# PY32L0xx_DFP register map
Vendor: Puya; Series: PY32L0; File version: 1.0.0
CPU: CM0+ r0p1, little endian, no MPU, no FPU, 4 interrupt priority bits
Registers are 32-bit, read-write, reset 0x0 unless marked. A register's access mark holds for its fields unless they carry their own. Offsets are from the block's base; [hi:lo] are bit positions; {n}, {i} and the like mark numbered series.

## IWDG — Independent watchdog
Base 0x40003000
0x00 KR wo — Key register (IWDG_KR)
  [15:0] KEY — Key value
0x04 PR — Prescaler register (IWDG_PR)
  [2:0] PR — Prescaler divider
0x08 RLR reset 0xFFF — Reload register (IWDG_RLR)
  [11:0] RL — Watchdog counter reload value
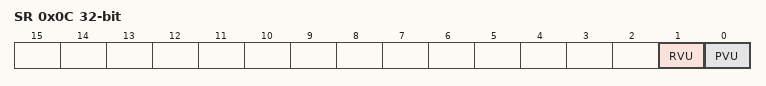
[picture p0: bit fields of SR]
0x0C SR ro — Status register (IWDG_SR)
  [1] RVU — Watchdog counter reload value update
  [0] PVU — Watchdog prescaler value update

## TIM1 — Advanced timer
Base 0x40012C00
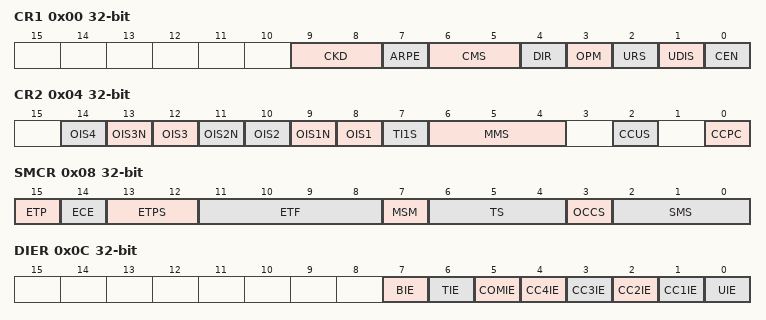
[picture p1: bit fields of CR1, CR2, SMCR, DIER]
0x00 CR1
  [9:8] CKD, [7] ARPE, [6:5] CMS, [4] DIR, [3] OPM, [2] URS, [1] UDIS, [0] CEN
0x04 CR2 (reset mask 0xF8)
  [2n+6] OIS{n} (n=1..4), [13] OIS3N, [11] OIS2N, [9] OIS1N, [7] TI1S, [6:4] MMS, [2] CCUS, [0] CCPC
0x08 SMCR (reset mask 0xFFF7)
  [15] ETP, [14] ECE, [13:12] ETPS, [11:8] ETF, [7] MSM, [6:4] TS, [3] OCCS, [2:0] SMS
0x0C DIER (reset mask 0x5F5F)
  [7] BIE, [6] TIE, [5] COMIE, [n] CC{n}IE (n=1..4), [0] UIE
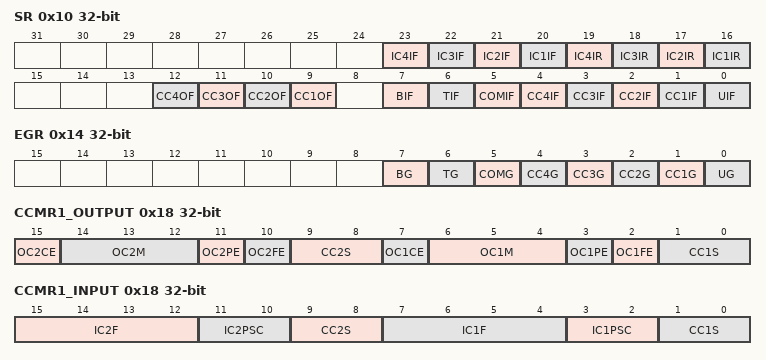
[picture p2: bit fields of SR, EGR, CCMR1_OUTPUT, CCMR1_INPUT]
0x10 SR (reset mask 0x1E5F)
  [23] IC4IF — desc IC3IF
  [22] IC3IF
  [21] IC2IF
  [20] IC1IF
  [19] IC4IR — desc IC3IR
  [18] IC3IR
  [17] IC2IR
  [16] IC1IR
  [n+8] CC{n}OF (n=1..4)
  [7] BIF
  [6] TIF
  [5] COMIF
  [n] CC{n}IF (n=1..4)
  [0] UIF
0x14 EGR wo (reset mask 0x5F)
  [7] BG
  [6] TG
  [5] COMG
  [4] CC4G
  [3] CC3G
  [2] CC2G
  [1] CC1G — Capture/Compare 1 Generation
  [0] UG
0x18 CCMR1_OUTPUT
  [15] OC2CE, [14:12] OC2M, [11] OC2PE, [10] OC2FE, [9:8] CC2S, [7] OC1CE, [6:4] OC1M, [3] OC1PE, [2] OC1FE, [1:0] CC1S
0x18 CCMR1_INPUT (alternate view of CCMR1_OUTPUT)
  [15:12] IC2F, [11:10] IC2PSC, [9:8] CC2S, [7:4] IC1F, [3:2] IC1PSC, [1:0] CC1S
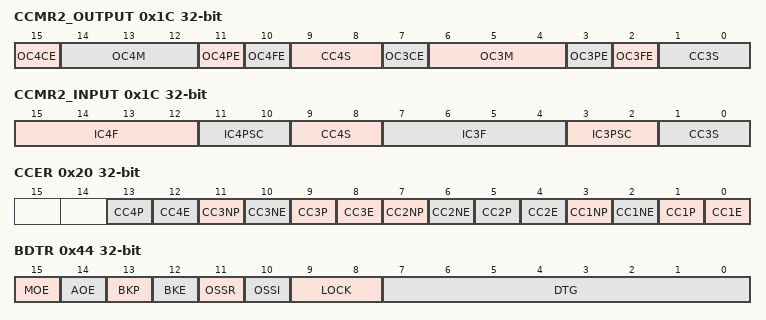
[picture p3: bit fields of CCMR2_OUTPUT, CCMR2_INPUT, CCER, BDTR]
0x1C CCMR2_OUTPUT
  [15] OC4CE, [14:12] OC4M, [11] OC4PE, [10] OC4FE, [9:8] CC4S, [7] OC3CE, [6:4] OC3M, [3] OC3PE, [2] OC3FE, [1:0] CC3S
0x1C CCMR2_INPUT (alternate view of CCMR2_OUTPUT)
  [15:12] IC4F, [11:10] IC4PSC, [9:8] CC4S, [7:4] IC3F, [3:2] IC3PSC, [1:0] CC3S
0x20 CCER (reset mask 0x3333)
  [4n-3] CC{n}P (n=1..4), [4n-4] CC{n}E (n=1..4), [11] CC3NP, [10] CC3NE, [7] CC2NP, [6] CC2NE, [3] CC1NP, [2] CC1NE
0x24 CNT
  [15:0] CNT
0x28 PSC
  [15:0] PSC
0x2C ARR reset 0xFFFF
  [15:0] ARR
0x30 RCR reset 0xFFFF
  [7:0] REP
{0x30+4i} CCR{i} (i=1..4)
  [15:0] CCR{i}
0x44 BDTR
  [15] MOE, [14] AOE, [13] BKP, [12] BKE, [11] OSSR, [10] OSSI, [9:8] LOCK, [7:0] DTG

## TIM14 — General purpose timer
Base 0x40002000
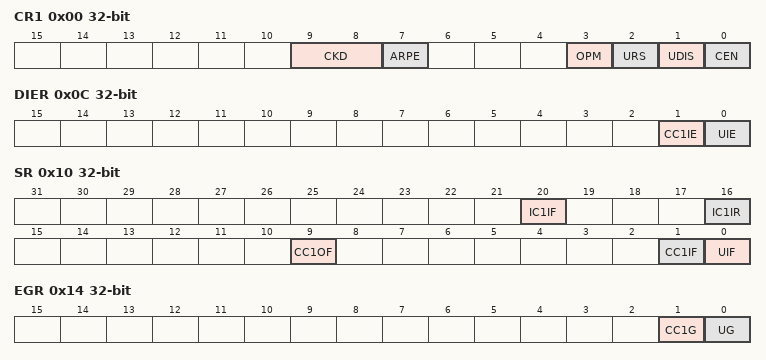
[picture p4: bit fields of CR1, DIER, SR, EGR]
0x00 CR1
  [9:8] CKD, [7] ARPE, [3] OPM, [2] URS, [1] UDIS, [0] CEN
0x0C DIER
  [1] CC1IE, [0] UIE
0x10 SR (reset mask 0x1E5F)
  [20] IC1IF, [16] IC1IR, [9] CC1OF, [1] CC1IF, [0] UIF
0x14 EGR wo
  [1] CC1G — Capture/Compare 1 Generation
  [0] UG
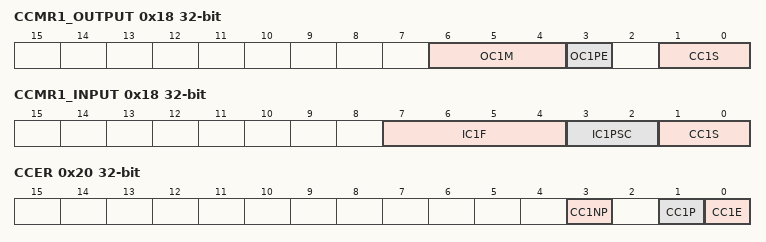
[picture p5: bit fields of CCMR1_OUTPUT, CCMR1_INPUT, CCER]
0x18 CCMR1_OUTPUT
  [6:4] OC1M, [3] OC1PE, [1:0] CC1S
0x18 CCMR1_INPUT (alternate view of CCMR1_OUTPUT)
  [7:4] IC1F, [3:2] IC1PSC, [1:0] CC1S
0x20 CCER (reset mask 0x3333)
  [3] CC1NP, [1] CC1P, [0] CC1E
0x24 CNT
  [15:0] CNT
0x28 PSC
  [15:0] PSC
0x2C ARR reset 0xFFFF
  [15:0] ARR
0x34 CCR1
  [15:0] CCR1
0x50 OR
  [1:0] TI1_RMP

## SYSCFG — System configuration controller
Base 0x40010000
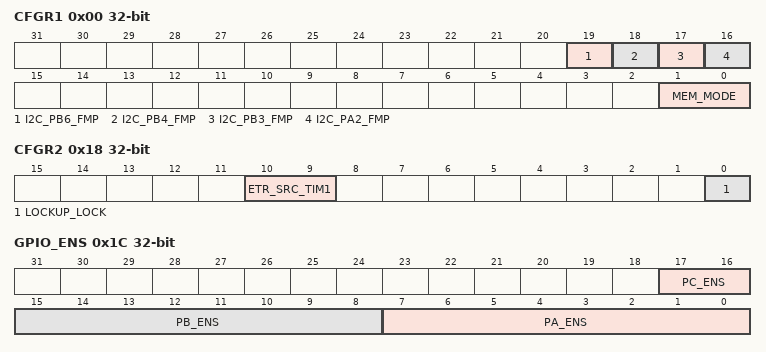
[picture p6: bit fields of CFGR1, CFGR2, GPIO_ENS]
0x00 CFGR1 — SYSCFG configuration register 1
  [19] I2C_PB6_FMP
  [18] I2C_PB4_FMP
  [17] I2C_PB3_FMP
  [16] I2C_PA2_FMP
  [1:0] MEM_MODE — Memory mapping selection bits
0x18 CFGR2 — SYSCFG configuration register 2
  [10:9] ETR_SRC_TIM1 — TIM1 ETR source selection
  [0] LOCKUP_LOCK — Cortex-M0+ LOCKUP bit enable bit
0x1C GPIO_ENS
  [17:16] PC_ENS, [15:8] PB_ENS, [7:0] PA_ENS

## FLASH
Base 0x40022000
0x00 ACR reset 0x600 — Access control register
  [0] LATENCY
0x08 KEYR wo — Flash key register
  [31:0] KEY — Flash key
0x0C OPTKEYR wo — Option byte key register
  [31:0] OPTKEY — Option byte key
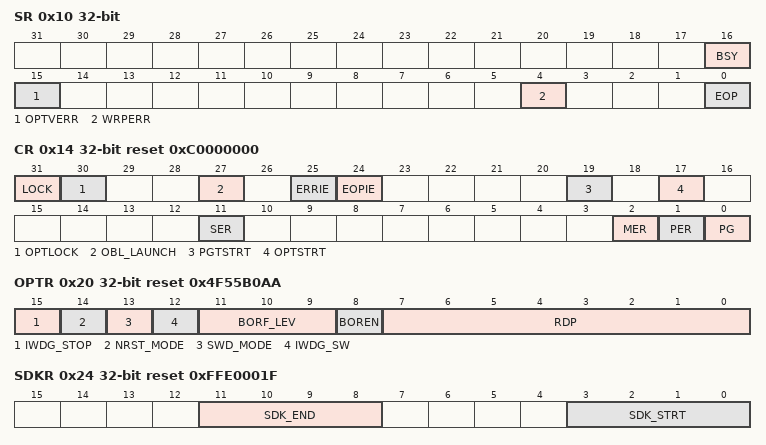
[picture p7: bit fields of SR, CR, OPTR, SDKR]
0x10 SR — Status register
  [16] BSY — Busy
  [15] OPTVERR — Option and Engineering bits loading validity error
  [4] WRPERR — Write protected error
  [0] EOP — End of operation
0x14 CR reset 0xC0000000 — Flash control register
  [31] LOCK — FLASH_CR Lock
  [30] OPTLOCK — Options Lock
  [27] OBL_LAUNCH — Force the option byte loading
  [25] ERRIE — Error interrupt enable
  [24] EOPIE — End of operation interrupt enable
  [19] PGTSTRT — Flash main memory program start
  [17] OPTSTRT — Option byte program start
  [11] SER — Sector erase
  [2] MER — Mass erase
  [1] PER — Page erase
  [0] PG — Programming
0x20 OPTR reset 0x4F55B0AA — Flash option register
  [15] IWDG_STOP
  [14] NRST_MODE
  [13] SWD_MODE
  [12] IWDG_SW — Independent watchdog selection
  [11:9] BORF_LEV — These bits contain the VDD supply level threshold that activates the reset
  [8] BOREN — BOR reset Level
  [7:0] RDP — Read Protection
0x24 SDKR reset 0xFFE0001F — Flash SDK address register
  [11:8] SDK_END — SDK area end address
  [3:0] SDK_STRT — SDK area start address
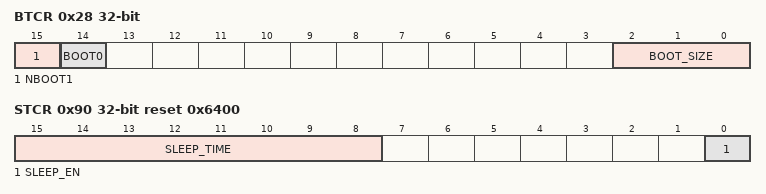
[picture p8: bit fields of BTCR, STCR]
0x28 BTCR — FLASH boot control register
  [15] NBOOT1, [14] BOOT0, [2:0] BOOT_SIZE
0x2C WRPR reset 0xFFFF — Flash WRP address register
  [5:0] WRP — WRP address
0x90 STCR reset 0x6400 — Flash sleep time config register
  [15:8] SLEEP_TIME — FLash sleep time configuration(counter based on HSI_10M)
  [0] SLEEP_EN — FLash sleep enable
0x100 TS0 reset 0xB4 — Flash TS0 register
  [8:0] TS0 — FLash TS0 register
0x104 TS1 reset 0x1B0 — Flash TS1 register
  [9:0] TS1 — FLash TS1 register
0x108 TS2P reset 0xB4 — Flash TS2P register
  [8:0] TS2P — FLash TS2P register
0x10C TPS3 reset 0x6C0 — Flash TPS3 register
  [11:0] TPS3 — FLash TPS3 register
0x110 TS3 reset 0xB4 — Flash TS3 register
  [8:0] TS3 — FLash TS3 register
0x114 PERTPE reset 0x14820 — Flash PERTPE register
  [17:0] PERTPE — FLash PERTPE register
0x118 SMERTPE reset 0x14820 — Flash SMERTPE register
  [17:0] SMERTPE — FLash SMERTPE register
0x11C PRGTPE reset 0x5DC0 — Flash PRGTPE register
  [15:0] PRGTPE — FLash PRGTPE register
0x120 PRETPE reset 0x12C0 — Flash PRETPE register
  [13:0] PRETPE — FLash PRETPE register

## CRC — CRC calculation unit
Base 0x40023000
0x00 DR reset 0xFFFFFFFF — Data register
  [31:0] DR — Data Register
0x04 IDR — Independent Data register
  [7:0] IDR
0x08 CR wo — Control register
  [0] RESET — Reset bit

## SPI1 — Serial peripheral interface
Base 0x40013000
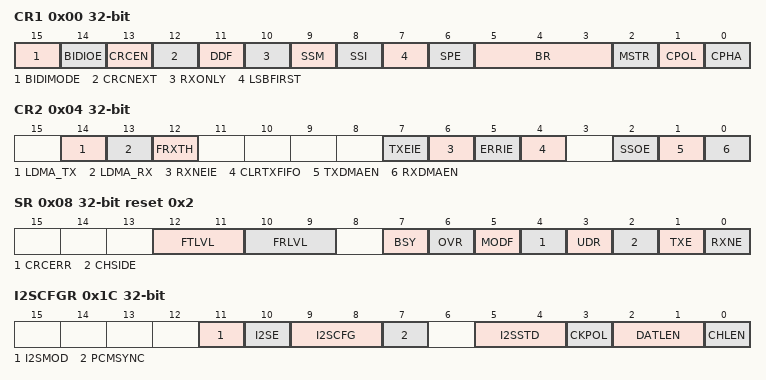
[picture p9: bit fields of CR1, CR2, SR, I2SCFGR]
0x00 CR1
  [15] BIDIMODE, [14] BIDIOE, [13] CRCEN, [12] CRCNEXT, [11] DDF, [10] RXONLY, [9] SSM, [8] SSI, [7] LSBFIRST, [6] SPE, [5:3] BR, [2] MSTR, [1] CPOL, [0] CPHA
0x04 CR2
  [14] LDMA_TX, [13] LDMA_RX, [12] FRXTH, [7] TXEIE, [6] RXNEIE, [5] ERRIE, [4] CLRTXFIFO, [2] SSOE, [1] TXDMAEN, [0] RXDMAEN
0x08 SR reset 0x2
  [12:11] FTLVL ro, [10:9] FRLVL ro, [7] BSY ro, [6] OVR ro, [5] MODF ro, [4] CRCERR, [3] UDR ro, [2] CHSIDE ro, [1] TXE ro, [0] RXNE ro
0x0C DR
  [15:0] DR
0x10 CRCPR reset 0x7
  [15:0] CRCPOLY
0x14 RXCRCR ro
  [15:0] RXCRC
0x18 TXCRCR ro
  [15:0] TXCRC
0x1C I2SCFGR
  [11] I2SMOD, [10] I2SE, [9:8] I2SCFG, [7] PCMSYNC, [5:4] I2SSTD, [3] CKPOL, [2:1] DATLEN, [0] CHLEN
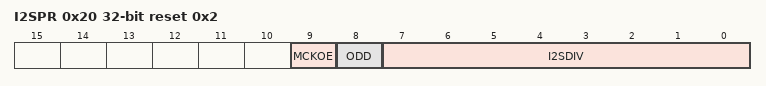
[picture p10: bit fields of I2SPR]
0x20 I2SPR reset 0x2
  [9] MCKOE, [8] ODD, [7:0] I2SDIV

## I2C — Inter integrated circuit
Base 0x40005400
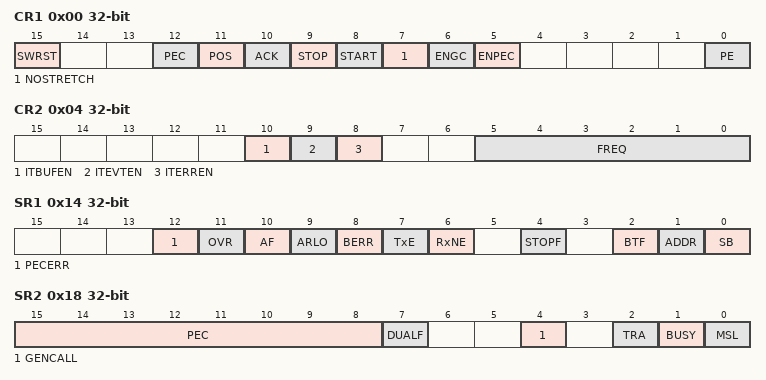
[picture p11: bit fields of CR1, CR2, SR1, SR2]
0x00 CR1 — Control register 1
  [15] SWRST — Software reset
  [12] PEC — Packet error checking
  [11] POS — Acknowledge/PEC Position (for datareception)
  [10] ACK — Acknowledge enable
  [9] STOP — Stop generation
  [8] START — Start generation
  [7] NOSTRETCH — Clock stretching disable (Slavemode)
  [6] ENGC — General call enable
  [5] ENPEC — PEC enable
  [0] PE — Peripheral enable
0x04 CR2 — Control register 2
  [10] ITBUFEN — Buffer interrupt enable
  [9] ITEVTEN — Event interrupt enable
  [8] ITERREN — Error interrupt enable
  [5:0] FREQ — Peripheral clock frequency
0x08 OAR1 — Own address register 1
  [7:1] ADD — Interface address
0x10 DR — Data register
  [7:0] DR — 8-bit data register
0x14 SR1 — Status register 1
  [12] PECERR — PEC Error in reception
  [11] OVR — Overrun/Underrun
  [10] AF — Acknowledge failure
  [9] ARLO — Arbitration lost (mastermode)
  [8] BERR — Bus error
  [7] TxE ro — Data register empty(transmitters)
  [6] RxNE ro — Data register not empty(receivers)
  [4] STOPF ro — Stop detection (slavemode)
  [2] BTF ro — Byte transfer finished
  [1] ADDR ro — Address sent (master mode)/matched(slave mode)
  [0] SB ro — Start bit (Master mode)
0x18 SR2 ro — Status register 2
  [15:8] PEC — acket error checkingregister
  [7] DUALF — Dual flag (Slave mode)
  [4] GENCALL — General call address (Slavemode)
  [2] TRA — Transmitter/receiver
  [1] BUSY — Bus busy
  [0] MSL — Master/slave
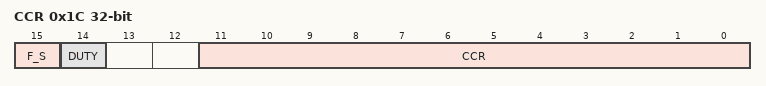
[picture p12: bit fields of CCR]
0x1C CCR — Clock control register
  [15] F_S — I2C master mode selection
  [14] DUTY — Fast mode duty cycle
  [11:0] CCR — Clock control register in Fast/Standardmode (Master mode)
0x20 TRISE reset 0x2
  [5:0] TRISE — Maximum rise time in Fast/Standard mode(Master mode)

## DBGMCU — Debug support
Base 0x40015800
0x00 IDCODE ro — MCU Device ID Code Register
  [31:0] REV_ID
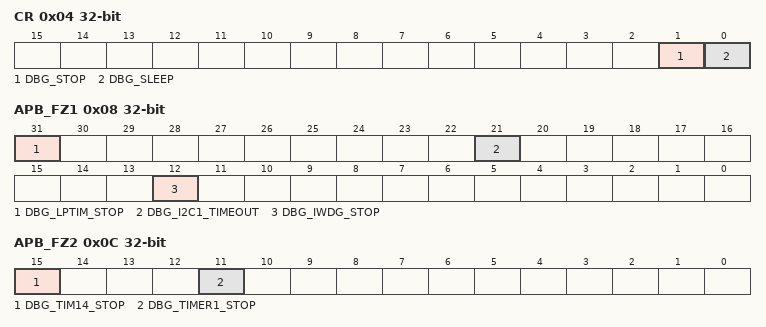
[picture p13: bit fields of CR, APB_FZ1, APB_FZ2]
0x04 CR — Debug MCU Configuration Register
  [1] DBG_STOP — Debug Stop Mode
  [0] DBG_SLEEP — Debug Sleep Mode
0x08 APB_FZ1 — APB Freeze Register1
  [31] DBG_LPTIM_STOP — Debug LPTIM stopped when Core ishalted
  [21] DBG_I2C1_TIMEOUT — Debug I2C1 TIMEOUT stopped when Core ishalted
  [12] DBG_IWDG_STOP — Debug Independent Wachdog stopped whenCore is halted
0x0C APB_FZ2 — APB Freeze Register2
  [15] DBG_TIM14_STOP — Debug TIM 14 stopped whenCore is halted
  [11] DBG_TIMER1_STOP — Debug Timer 1 stopped when Core ishalted
